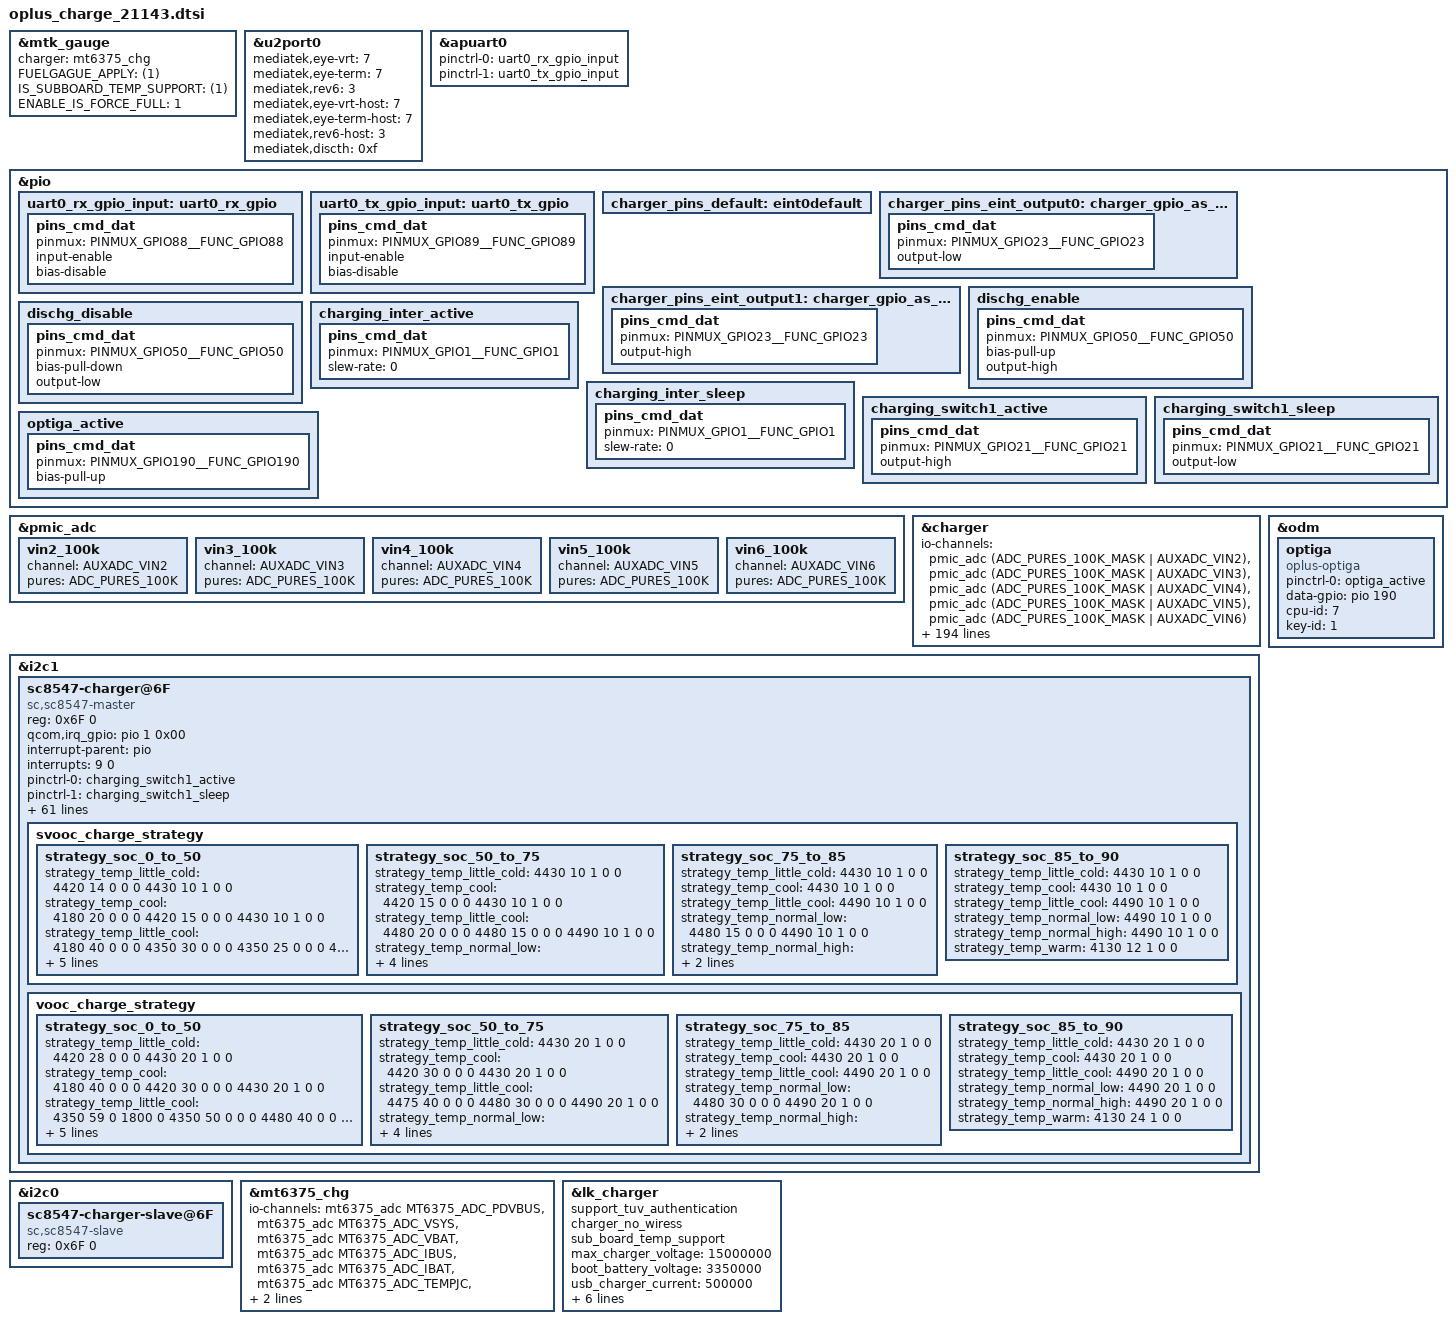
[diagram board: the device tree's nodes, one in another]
// SPDX-License-Identifier: GPL-2.0-only
/*
* Copyright (C) 2021-2020 Oplus. All rights reserved.
*/
#include <dt-bindings/iio/mt635x-auxadc.h>
#include <dt-bindings/pinctrl/mt6373-pinfunc.h>
#include <dt-bindings/pinctrl/mt65xx.h>
#include "oplus_chg.h"
#include <dt-bindings/iio/adc/mediatek,mt6375_adc.h>



&mtk_gauge {
	status = "okay";
	charger = <&mt6375_chg>;
	FUELGAGUE_APPLY = <(1)>;
	IS_SUBBOARD_TEMP_SUPPORT = <(1)>;
	ENABLE_IS_FORCE_FULL = <1>;
	#include "mediatek/bat_setting/mt6893_21143_battery_table_ext.dtsi"
	#include "mediatek/bat_setting/mt6893_21143_battery_prop_dim2_ext.dtsi"
};

&u2port0 {
	mediatek,eye-vrt = <7>;
	mediatek,eye-term = <7>;
	mediatek,rev6 = <3>;
	mediatek,eye-vrt-host = <7>;
	mediatek,eye-term-host = <7>;
	mediatek,rev6-host = <3>;
	mediatek,discth = <0xf>;
};

&apuart0 {
	pinctrl-names = "uart0_rx_gpio", "uart0_tx_gpio";
	pinctrl-0 = <&uart0_rx_gpio_input>;
	pinctrl-1 = <&uart0_tx_gpio_input>;
	status = "okay";
};

&pio {
	uart0_rx_gpio_input: uart0_rx_gpio {
		pins_cmd_dat {
			pinmux = <PINMUX_GPIO88__FUNC_GPIO88>;
			input-enable;
			bias-disable;
		};
	};

	uart0_tx_gpio_input: uart0_tx_gpio {
		pins_cmd_dat {
			pinmux = <PINMUX_GPIO89__FUNC_GPIO89>;
			input-enable;
			bias-disable;
		};
	};
};

&pmic_adc {
	vin2_100k {
		channel = <AUXADC_VIN2>;
		pures = <ADC_PURES_100K>;
	};
	vin3_100k {
		channel = <AUXADC_VIN3>;
		pures = <ADC_PURES_100K>;
	};
	vin4_100k {
		channel = <AUXADC_VIN4>;
		pures = <ADC_PURES_100K>;
	};
	vin5_100k {
		channel = <AUXADC_VIN5>;
		pures = <ADC_PURES_100K>;
	};
	vin6_100k {
		channel = <AUXADC_VIN6>;
		pures = <ADC_PURES_100K>;
	};
};

&charger {

	io-channels = <&pmic_adc (ADC_PURES_100K_MASK | AUXADC_VIN2)>,
			<&pmic_adc (ADC_PURES_100K_MASK | AUXADC_VIN3)>,
			<&pmic_adc (ADC_PURES_100K_MASK | AUXADC_VIN4)>,
			<&pmic_adc (ADC_PURES_100K_MASK | AUXADC_VIN5)>,
			<&pmic_adc (ADC_PURES_100K_MASK | AUXADC_VIN6)>;
	io-channel-names = "auxadc2_ntc_sub_bat_tem",
			"usb_temp_v_l",
			"usb_temp_v_r",
			"auxadc5_batt_btb_temp",
			"auxadc6_usb_btb_temp";

	pinctrl-names = "default",
			"charger_gpio_as_output_low",  /*Level 1 switch*/
			"charger_gpio_as_output_high",
			"dischg_enable",  /*Prevent burning control*/
			"dischg_disable";

	pinctrl-0 = <&charger_pins_default>;
	pinctrl-1 = <&charger_pins_eint_output0>;
	pinctrl-2 = <&charger_pins_eint_output1>;
	pinctrl-3 = <&dischg_enable>;
	pinctrl-4 = <&dischg_disable>;


	//for oplus chg framework:
	qcom,pd_input_current_charger_ma = <1500>;
	qcom,qc_input_current_charger_ma = <2000>;
	qcom,input_current_charger_ma = <2200>;
	qcom,input_current_usb_ma = <500>;
	qcom,input_current_cdp_ma = <1500>;
	qcom,input_current_camera_ma = <1200>;
	qcom,input_current_calling_ma = <1500>;

	qcom,led_warm_bat_decidegc = <350>;
	qcom,led_high_bat_decidegc = <370>;
	qcom,input_current_led_ma = <1200>;
	qcom,input_current_led_ma_high = <1200>;
	qcom,input_current_led_ma_warm = <1500>;
	qcom,input_current_led_ma_normal = <2300>;
	qcom,input_current_led_ma_forcmcc = <500>;
	qcom,input_current_led_ma_limit_high = <1200>;

	qcom,vooc_temp_bat_normal_decidegc = <350>;
	qcom,vooc_temp_bat_warm_decidegc = <370>;
	qcom,vooc_temp_bat_hot_decidegc = <440>;
	qcom,input_current_vooc_led_ma_high = <1200>;
	qcom,input_current_vooc_led_ma_warm = <1800>;
	qcom,input_current_vooc_led_ma_normal = <3600>;
	qcom,input_current_vooc_ma_normal = <3600>;
	qcom,input_current_vooc_ma_warm = <3200>;
	qcom,input_current_vooc_ma_high = <2200>;

	qcom,overtemp_bat_decidegc = <350>;
	qcom,iterm_disabled = <0>;
	//sw_full_count = <25>;
	qcom,iterm_ma = <230>;
	qcom,recharge-mv = <100>;

	qcom,batt_capacity_mah = <4500>; /*typical capacity*/
	//qcom,batt_capacity_mah = <4880>; /*rated capacity*/
	qcom,usb_high_than_bat_decidegc = <168>;

	qcom,removed_bat_decidegc = <150>;  /* < -15C */

	qcom,cold_bat_decidegc = <100>;  /* -10C ~ 0C */
	qcom,temp_cold_vfloat_mv = <3980>;
	qcom,temp_cold_fastchg_current_ma = <360>;

	qcom,little_cold_bat_decidegc = <0>;    /* 0C ~ 5C */
	qcom,temp_little_cold_vfloat_mv = <4435>;
	qcom,temp_little_cold_fastchg_current_ma_high = <2200>;
	qcom,temp_little_cold_fastchg_current_ma_low = <2200>;
	qcom,temp_little_cold_fastchg_current_ma = <1076>;
	qcom,qc_temp_little_cold_fastchg_current_ma_high = <2594>;
	qcom,qc_temp_little_cold_fastchg_current_ma_low = <3300>;
	qcom,pd_temp_little_cold_fastchg_current_ma_high = <2594>;
	qcom,pd_temp_little_cold_fastchg_current_ma_low = <3300>;

	qcom,cool_bat_decidegc = <50>;  /* 5C ~ 12C */
	qcom,temp_cool_vfloat_mv = <4435>;
	qcom,temp_cool_fastchg_current_ma_high = <2200>;
	qcom,temp_cool_fastchg_current_ma_low = <2200>;
	qcom,qc_temp_cool_fastchg_current_ma_high = <3300>;
	qcom,qc_temp_cool_fastchg_current_ma_low = <3300>;
	qcom,pd_temp_cool_fastchg_current_ma_high = <3300>;
	qcom,pd_temp_cool_fastchg_current_ma_low = <3300>;

	qcom,little_cool_bat_decidegc = <120>;  /* 12C ~ 16C */
	qcom,temp_little_cool_vfloat_mv = <4435>;
	qcom,temp_little_cool_fastchg_current_ma = <2200>;
	qcom,pd_temp_little_cool_fastchg_current_ma = <3300>;
	qcom,qc_temp_little_cool_fastchg_current_ma = <3300>;

	qcom,normal_bat_decidegc = <160>;       /* 16C ~ 45C */
	qcom,temp_normal_vfloat_mv = <4435>;
	qcom,temp_normal_fastchg_current_ma = <2200>;
	qcom,pd_temp_normal_fastchg_current_ma = <3300>;
	qcom,qc_temp_normal_fastchg_current_ma = <3300>;

	qcom,warm_bat_decidegc = <450>;         /* 45C ~ 53C */ /*8pin Bat Vooc project need add 3 degree C*/
	qcom,temp_warm_vfloat_mv = <4130>;
	qcom,temp_warm_fastchg_current_ma = <1152>;
	qcom,pd_temp_warm_fastchg_current_ma = <1152>;
	qcom,qc_temp_warm_fastchg_current_ma = <1152>;
	qcom,temp_warm_fastchg_current_ma_led_on = <500>;

	qcom,hot_bat_decidegc = <530>;  /* > 53C */

	qcom,non_standard_vfloat_mv = <3980>;
	qcom,non_standard_fastchg_current_ma = <512>;

	qcom,short_c_bat_cv_mv = <4330>;
	qcom,short_c_bat_vfloat_mv = <3800>;
	qcom,short_c_bat_fastchg_current_ma = <512>;
	qcom,short_c_bat_vfloat_sw_limit = <3750>;

	qcom,cold_vfloat_sw_limit = <3930>;
	qcom,little_cold_vfloat_sw_limit = <4385>;
	qcom,cool_vfloat_sw_limit = <4385>;
	qcom,little_cool_vfloat_sw_limit = <4385>;
	qcom,normal_vfloat_sw_limit = <4385>;
	qcom,warm_vfloat_sw_limit = <4080>;
	qcom,non_standard_vfloat_sw_limit = <3930>;

	qcom,max_chg_time_sec = <70272>;
	qcom,charger_hv_thr = <10000>;
	qcom,charger_recv_thr = <9800>;
	qcom,charger_lv_thr = <3400>;
	qcom,vbatt_full_thr = <4400>;
	qcom,vbatt_hv_thr = <4550>;

	qcom,vfloat_step_mv = <16>;
	qcom,non_standard_vfloat_over_sw_limit = <3980>;
	qcom,cold_vfloat_over_sw_limit = <3980>;
	qcom,little_cold_vfloat_over_sw_limit = <4440>;
	qcom,cool_vfloat_over_sw_limit = <4440>;
	qcom,little_cool_vfloat_over_sw_limit = <4440>;
	qcom,normal_vfloat_over_sw_limit = <4440>;
	qcom,warm_vfloat_over_sw_limit = <4130>;

	qcom,vbatt_power_off = <3300>;
	qcom,vbatt_soc_1 = <3410>;
	qcom,vooc_project = <6>;
	qcom,vbatt_num = <1>;
	qcom,new_ui_warning_support;
	qcom,smart_charging_screenoff;
	qcom,smart_charge_version = <1>;

	qcom,normal_vterm_hw_inc = <18>;
	qcom,non_normal_vterm_hw_inc = <18>;
	qcom,usbtemp_batttemp_gap = <12>;

	qcom,ff1_normal_fastchg_ma = <1650>;
	qcom,ff1_warm_fastchg_ma = <1750>;	/* 35C ~ 40c */
	qcom,ff1_exit_step_ma = <200>;
	qcom,ff1_warm_exit_step_ma = <200>;
	qcom,ffc2_normal_fastchg_ma = <1650>;/*12C~35c*/
	qcom,ffc2_warm_fastchg_ma = <1750>;	/* 35C ~ 40c */
	qcom,ffc2_temp_warm_decidegc = <350>;
	qcom,ffc2_temp_high_decidegc = <400>;
	qcom,ffc2_temp_low_decidegc = <160>;
	qcom,ffc2_exit_step_ma = <200>;
	qcom,ffc2_warm_exit_step_ma = <200>;

	qcom,ffc_normal_vfloat_sw_limit = <4485>;
	qcom,ffc2_normal_vfloat_sw_limit = <4485>;
	qcom,ffc_temp_normal_vfloat_mv = <4550>;
	qcom,ffc_normal_vfloat_over_sw_limit = <4550>;

	qcom,default_iterm_ma = <230>;
	qcom,default_temp_normal_fastchg_current_ma = <2200>;
	qcom,default_normal_vfloat_sw_limit = <4385>;
	qcom,default_temp_normal_vfloat_mv = <4435>;
	qcom,default_normal_vfloat_over_sw_limit = <4440>;
	qcom,default_temp_little_cool_fastchg_current_ma = <1100>;
	qcom,default_little_cool_vfloat_sw_limit = <4385>;
	qcom,default_temp_little_cool_vfloat_mv = <4435>;
	qcom,default_little_cool_vfloat_over_sw_limit = <4445>;

	//for PD9V or QC9V
	qcom,vbatt_pdqc_to_5v_thr = <4500>;
	qcom,vbatt_pdqc_to_9v_thr = <4500>;

	//for control:
	//qcom,suspend_after_full;
	qcom,check_batt_full_by_sw;
	qcom,chg_ctrl_by_lcd;
	qcom,chg_ctrl_by_camera;
	qcom,chg_ctrl_by_calling;
	qcom,sw_vfloat_over_protect_enable;
	qcom,usbtemp_dischg_by_platpmic;
	qcom,ffc_support;
	qcom,chargerid_vol_disable;
	qcom,support_ntc_01c_precision;
	qcom,voocphy_support = <3>;
	qcom,external_authenticate;
	qcom,chargerid_support;
	qcom,vooc_show_ui_soc_decimal;
	qcom,ui_soc_decimal_speedmin = <20>;//2A
	qcom,ccdetect_by_wd0;
	//GPIO config:
	qcom,chargerid_switch-gpio = <&pio 23 0x00>;
	qcom,dischg-gpio = <&pio 50 0x00>;

	qcom,vooc-max-input-volt-support = <11000>;     //10V
	qcom,vooc-max-input-current-support = <3000>;   //6.5A
};

/*#ifdef OPLUS_FEATURE_CHG_BASIC*/
&charger {
	//oplus,pps_ops = "cp-sc8571";
	qcom,pps_support_type = <0>;
	qcom,pps_warm_allow_vol = <4000>;
	qcom,pps_warm_allow_soc = <50>;
	qcom,pps_strategy_normal_current = <8000>;//6A
	qcom,pps_over_high_or_low_current = <8000>;
	qcom,pps_full_cool_sw_vbat = <4430>;
	qcom,pps_full_normal_sw_vbat = <4490>;
	qcom,pps_full_normal_hw_vbat = <4500>;
	qcom,pps_full_ffc_vbat = <4420>;
	qcom,pps_warm_full_voltage = <4130>;
	qcom,pps_full_cool_sw_vbat_30w = <4430>;
	qcom,pps_full_normal_sw_vbat_30w = <4430>;
	qcom,pps_full_normal_hw_vbat_30w = <4440>;
	oplus,pps_r_default = <120 10 10 15 15 15 15>;
	oplus,pps_rmos_mohm = <4>;
	oplus,pps_r_limit = <280 200 140 90 50>;
	oplus,pps_strategy_batt_high_temp = <425 430 435 400 415 420>;
	oplus,pps_strategy_high_current = <8000 8000 8000 8000 8000 8000>;
	oplus,pps_charge_strategy_soc = <0 15 35 55 75 85 95>;
	oplus,pps_charge_strategy_temp = <0 50 120 200 350 440 510>;
	oplus,pps_low_curr_full_strategy_temp = <120 200 350 440>;
};
/*endif OPLUS_FEATURE_CHG_BASIC*/

&i2c1 {
	status = "okay";
	sc8547-charger@6F{
		status = "okay";
		compatible = "sc,sc8547-master";
		reg = <0x6F 0>;

		qcom,irq_gpio = <&pio 1 0x00>;
		interrupt-parent = <&pio>;
		interrupts = <9 0>;

		pinctrl-names = "switch1_act_switch2_act", "switch1_sleep_switch2_sleep",
					"charging_inter_active", "charging_inter_sleep";
		pinctrl-0 = <&charging_switch1_active>; 
		pinctrl-1 = <&charging_switch1_sleep>;
		pinctrl-2 = <&charging_inter_active>;
		pinctrl-3 = <&charging_inter_sleep>;

		qcom,charging_switch1-gpio = <&pio 21 0x00>;

		qcom,voocphy_dual_cp_support;
		qcom,slave_cp_enable_thr = <1400>;		//2000-100mA
		qcom,slave_cp_disable_thr_high = <1100>;	//1500+100mA
		qcom,voocphy_current_default = <60>;

		qcom,svooc_cool_down_current_limit = <120 20 20 20 30 40 50 60 70 80 90 100>;
		qcom,vooc_cool_down_current_limit = <60 20 20 20 30 40 50 60>;

		qcom,vooc_multistep_initial_batt_temp = <1000>;
		qcom,vooc_little_cool_temp = <160>;
		qcom,vooc_cool_temp = <120>;
		qcom,vooc_little_cold_temp = <50>;
		qcom,vooc_normal_low_temp = <350>;
		qcom,vooc_strategy_normal_current = <120>;
		qcom,vooc_normal_to_little_cool_current = <100>;
		qcom,vooc_batt_over_high_temp = <510>;
		qcom,vooc-low-temp = <0>;

		qcom,vooc-high-temp = <500>;
		qcom,vooc-low-soc = <0>;
		qcom,vooc-high-soc = <90>;
		qcom,vooc-normal-high-temp = <430>;
		qcom,vooc-warm-allow-vol = <4000>;
		qcom,vooc-warm-allow-soc = <50>;

		qcom,vooc_strategy1_batt_high_temp0 = <385>;
		qcom,vooc_strategy1_batt_high_temp1 = <395>;
		qcom,vooc_strategy1_batt_high_temp2 = <420>;
		qcom,vooc_strategy1_batt_low_temp2 = <410>;
		qcom,vooc_strategy1_batt_low_temp1 = <385>;
		qcom,vooc_strategy1_batt_low_temp0 = <375>;

		qcom,vooc_strategy1_high_current0 = <80>;
		qcom,vooc_strategy1_high_current1 = <60>;
		qcom,vooc_strategy1_high_current2 = <40>;
		qcom,vooc_strategy1_low_current2 = <40>;
		qcom,vooc_strategy1_low_current1 = <60>;
		qcom,vooc_strategy1_low_current0 = <80>;

		qcom,voocphy_freq_mincore = <925000>;
		qcom,voocphy_freq_midcore = <1335000>;
		qcom,voocphy_freq_maxcore = <1350000>;
		qcom,voocphy_current_change_timeout = <100>;

		qcom,voocphy_ibat_over_current = <13500>;
		qcom,voocphy_svooc_cp_max_ibus = <3500>;
		qcom,voocphy_vooc_cp_max_ibus = <3500>;

		qcom,vooc_little_cold_full_voltage = <4430>;
		qcom,vooc_cool_full_voltage = <4430>;
		qcom,vooc_warm_full_voltage = <4130>;
		qcom,vooc_1time_full_voltage = <4490>;
		qcom,vooc_ntime_full_voltage = <4490>;
		qcom,low_curr_full_t1 = <120>;
		qcom,low_curr_full_t2 = <350>;
		qcom,low_curr_full_t3 = <430>;
		qcom,range1_low_curr_full = <1350 4490
						1250 4485
						1150 4470
						1050 4460
						950 4450>;
		qcom,range2_low_curr_full = <1600 4490
						1400 4485
						1300 4470
						1200 4460
						1100 4450>;

		svooc_batt_sys_curve = <0 1 0 1 0 0 0	// 4000mA
					1 1 1 1 0 0 0	// 4604mV
					0 0 1 1 0 1 0	// 2600mA
					1 1 1 1 0 0 0	// 4604mV
					0 0 0 1 0 1 1	// 1100mA
					1 1 1 1 0 0 0>;	// 4604mV

		vooc_batt_sys_curve =  <0 1 0 1 0 0 0	// 4000mA
					1 1 1 1 0 0 0	// 4604mV
					0 0 1 1 0 1 0	// 2600mA
					1 1 1 1 0 0 0	// 4604mV
					0 0 0 1 0 1 1	// 1100mA
					1 1 1 1 0 0 0>;	// 4604mV

		svooc_charge_strategy {
			strategy_soc_0_to_50 {
				strategy_temp_little_cold =	<4420 14 0 0 0
								 4430 10 1 0 0>;
				strategy_temp_cool =	<4180 20 0 0 0
								 4420 15 0 0 0
								 4430 10 1 0 0>;
				strategy_temp_little_cool =	<4180 40 0 0 0
								 4350 30 0 0 0
								 4350 25 0 0 0
								 4480 20 0 0 0
								 4480 15 0 0 0
								 4490 10 1 0 0>;
				strategy_temp_normal_low =	<4180 60 0 240 0 //min*60*1000/500
								 4200 50 0 600 0 //min*60*1000/500
								 4350 40 0 1200 0 //min*60*1000/500
								 4450 30 0 0 0
								 4450 25 0 0 0
								 4480 20 0 0 0
								 4480 15 0 0 0
								 4490 10 1 0 0>;
				strategy_temp_normal_high =	<4200 50 0 600 0 //min*60*1000/500
								 4350 40 0 1200 0 //min*60*1000/500
								 4450 30 0 0 0
								 4450 25 0 0 0
								 4480 20 0 0 0
								 4480 15 0 0 0
								 4490 10 1 0 0>;
				strategy_temp_warm = <4130 12 1 0 0>;
			};

			strategy_soc_50_to_75 {
				strategy_temp_little_cold =	<4430 10 1 0 0>;
				strategy_temp_cool =	<4420 15 0 0 0
								 4430 10 1 0 0>;
				strategy_temp_little_cool =	<4480 20 0 0 0
								 4480 15 0 0 0
								 4490 10 1 0 0>;
				strategy_temp_normal_low =	<4450 25 0 0 0
								 4480 20 0 0 0
								 4480 15 0 0 0
								 4490 10 1 0 0>;
				strategy_temp_normal_high =	<4450 25 0 0 0
								 4480 20 0 0 0
								 4480 15 0 0 0
								 4490 10 1 0 0>;
				strategy_temp_warm = <4130 12 1 0 0>;
			};

			strategy_soc_75_to_85 {
				strategy_temp_little_cold =	<4430 10 1 0 0>;
				strategy_temp_cool =	<4430 10 1 0 0>;
				strategy_temp_little_cool =	<4490 10 1 0 0>;
				strategy_temp_normal_low =	<4480 15 0 0 0
								 4490 10 1 0 0>;
				strategy_temp_normal_high =	<4480 15 0 0 0
								 4490 10 1 0 0>;
				strategy_temp_warm = <4130 12 1 0 0>;
			};

			strategy_soc_85_to_90 {
				strategy_temp_little_cold =	<4430 10 1 0 0>;
				strategy_temp_cool =	<4430 10 1 0 0>;
				strategy_temp_little_cool =	<4490 10 1 0 0>;
				strategy_temp_normal_low =	<4490 10 1 0 0>;
				strategy_temp_normal_high =	<4490 10 1 0 0>;
				strategy_temp_warm = <4130 12 1 0 0>;
			};
		};

		vooc_charge_strategy {
			strategy_soc_0_to_50 {
				strategy_temp_little_cold =	<4420 28 0 0 0
								 4430 20 1 0 0>;
				strategy_temp_cool =	<4180 40 0 0 0
								 4420 30 0 0 0
								 4430 20 1 0 0>;
				strategy_temp_little_cool =	<4350 59 0 1800 0
								 4350 50 0 0 0
								 4480 40 0 0 0
								 4480 30 0 0 0
								 4490 20 1 0 0>;
				strategy_temp_normal_low =	<4450 59 0 1800 0
								 4450 50 0 0 0
								 4480 40 0 0 0
								 4480 30 0 0 0
								 4490 20 1 0 0>;
				strategy_temp_normal_high =	<4450 59 0 1800 0
								 4450 50 0 0 0
								 4480 40 0 0 0
								 4480 30 0 0 0
								 4490 20 1 0 0>;
				strategy_temp_warm = <4130 24 1 0 0>;
			};

			strategy_soc_50_to_75 {
				strategy_temp_little_cold =	<4430 20 1 0 0>;
				strategy_temp_cool =	<4420 30 0 0 0
								 4430 20 1 0 0>;
				strategy_temp_little_cool =	<4475 40 0 0 0
								 4480 30 0 0 0
								 4490 20 1 0 0>;
				strategy_temp_normal_low =	<4450 50 0 0 0
								 4480 40 0 0 0
								 4480 30 0 0 0
								 4490 20 1 0 0>;
				strategy_temp_normal_high =	<4450 50 0 0 0
								 4480 40 0 0 0
								 4480 30 0 0 0
								 4490 20 1 0 0>;
				strategy_temp_warm = <4130 24 1 0 0>;
			};

			strategy_soc_75_to_85 {
				strategy_temp_little_cold =	<4430 20 1 0 0>;
				strategy_temp_cool =	<4430 20 1 0 0>;
				strategy_temp_little_cool =	<4490 20 1 0 0>;
				strategy_temp_normal_low =	<4480 30 0 0 0
								 4490 20 1 0 0>;
				strategy_temp_normal_high =	<4480 30 0 0 0
								 4490 20 1 0 0>;
				strategy_temp_warm = <4130 24 1 0 0>;
			};

			strategy_soc_85_to_90 {
				strategy_temp_little_cold =	<4430 20 1 0 0>;
				strategy_temp_cool =	<4430 20 1 0 0>;
				strategy_temp_little_cool =	<4490 20 1 0 0>;
				strategy_temp_normal_low =	<4490 20 1 0 0>;
				strategy_temp_normal_high =	<4490 20 1 0 0>;
				strategy_temp_warm = <4130 24 1 0 0>;
			};
		};

	};
};

&i2c0 {
	status = "okay";
	sc8547-charger-slave@6F{
		status = "okay";
		compatible = "sc,sc8547-slave";
		reg = <0x6F 0>;
	};
};

&pio {
	charger_pins_default: eint0default {
	};
	charger_pins_eint_output0: charger_gpio_as_output_low {
		pins_cmd_dat {
			pinmux = <PINMUX_GPIO23__FUNC_GPIO23>;
			output-low;
		};
	};

	charger_pins_eint_output1: charger_gpio_as_output_high {
		pins_cmd_dat {
			pinmux = <PINMUX_GPIO23__FUNC_GPIO23>;
			output-high;
		};
	};

	dischg_enable: dischg_enable {
		pins_cmd_dat {
			pinmux = <PINMUX_GPIO50__FUNC_GPIO50>;
			bias-pull-up;
			output-high;
		};
	};

	dischg_disable: dischg_disable {
		pins_cmd_dat {
			pinmux = <PINMUX_GPIO50__FUNC_GPIO50>;
			bias-pull-down;
			output-low;
		};
	};

	charging_inter_active: charging_inter_active {
		pins_cmd_dat {
			pinmux = <PINMUX_GPIO1__FUNC_GPIO1>;
			slew-rate = <0>;
		};
	};
	charging_inter_sleep: charging_inter_sleep {
		pins_cmd_dat {
			pinmux = <PINMUX_GPIO1__FUNC_GPIO1>;
			slew-rate = <0>;
		};
	};

	charging_switch1_active: charging_switch1_active {
		pins_cmd_dat {
			pinmux = <PINMUX_GPIO21__FUNC_GPIO21>;
			output-high;
		};
	};

	charging_switch1_sleep: charging_switch1_sleep {
		pins_cmd_dat {
			pinmux = <PINMUX_GPIO21__FUNC_GPIO21>;
			output-low;
		};
	};
};

&mt6375_chg {
	io-channels = <&mt6375_adc MT6375_ADC_PDVBUS>,
		      <&mt6375_adc MT6375_ADC_VSYS>,
		      <&mt6375_adc MT6375_ADC_VBAT>,
		      <&mt6375_adc MT6375_ADC_IBUS>,
		      <&mt6375_adc MT6375_ADC_IBAT>,
		      <&mt6375_adc MT6375_ADC_TEMPJC>,
		      <&mt6375_adc MT6375_ADC_USBDP>,
		      <&mt6375_adc MT6375_ADC_USBDM>;
};

&lk_charger {
	support_tuv_authentication;
	charger_no_wiress;
	sub_board_temp_support;
	max_charger_voltage = <15000000>;
	boot_battery_voltage = <3350000>;
	usb_charger_current = <500000>;
	ac_charger_current = <2050000>;
	ac_charger_input_current = <1500000>;
	non_std_ac_charger_current = <750000>;
	charging_host_charger_current = <1500000>;
	ta_ac_charger_current = <1500000>;
	pd_charger_current = <500000>;
};

&odm {
	optiga {
		compatible = "oplus-optiga";
		status = "ok";
		pinctrl-names = "optiga_active";
		pinctrl-0 = <&optiga_active>;
		data-gpio = <&pio 190 0x00>;
		cpu-id = <7>;
		key-id = <1>;
	};
};

&pio {
	optiga_active: optiga_active {
		pins_cmd_dat {
			pinmux = <PINMUX_GPIO190__FUNC_GPIO190>;
			//slew-rate = <1>;
			bias-pull-up;
		};
	};
};
